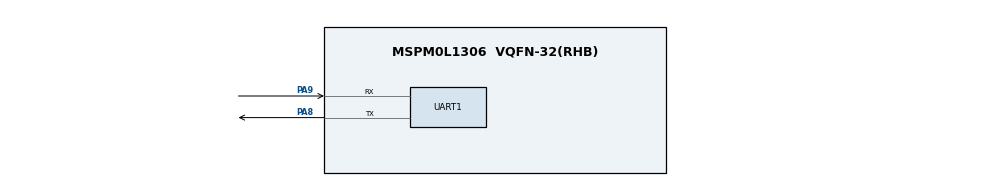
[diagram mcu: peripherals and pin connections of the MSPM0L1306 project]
// @cliArgs --board /ti/boards/LP_MSPM0L1306 --rtos nortos
//@cliArgs --device "MSPM0L130X" --package "VQFN-32(RHB)" --part "Default"
//@v2CliArgs --device "MSPM0L1306" --package "VQFN-32(RHB)"
// UART0 on PA8 (TX) / PA9 (RX), the XDS110 back-channel with J16/J17 on XDS.
// DMA ch0 = UART RX (byte -> memory), DMA ch1 = UART TX (memory -> byte).
// Baud rate is NOT set here: usart_dma.c overrides it from the build-time define USART_BAUD.
const SYSCTL = scripting.addModule("/ti/driverlib/SYSCTL");
const UART   = scripting.addModule("/ti/driverlib/UART", {}, false);
const UART1  = UART.addInstance();
const TIMER  = scripting.addModule("/ti/driverlib/TIMER", {}, false);
const TIMER1 = TIMER.addInstance();

SYSCTL.clockTreeEn = true;

UART1.$name                             = "UART_0";
UART1.profile                           = "CONFIG_PROFILE_1";
UART1.peripheral.$assign                = "UART0";
UART1.peripheral.txPin.$assign          = "PA8";
UART1.peripheral.rxPin.$assign          = "PA9";
UART1.targetBaudRate                    = 115200;
UART1.enableInternalLoopback            = false;
UART1.enableFIFO                        = true;
UART1.rxFifoThreshold                   = "DL_UART_RX_FIFO_LEVEL_ONE_ENTRY";
UART1.txFifoThreshold                   = "DL_UART_TX_FIFO_LEVEL_ONE_ENTRY";
UART1.enabledInterrupts                 = ["DMA_DONE_RX","DMA_DONE_TX"];
UART1.enabledDMARXTriggers              = "DL_UART_DMA_INTERRUPT_RX";
UART1.enabledDMATXTriggers              = "DL_UART_DMA_INTERRUPT_TX";
UART1.enableDMARX                       = true;
UART1.enableDMATX                       = true;
UART1.DMA_CHANNEL_RX.$name              = "DMA_RX";
UART1.DMA_CHANNEL_RX.addressMode        = "f2b";
UART1.DMA_CHANNEL_RX.dstIncDec          = "INCREMENT";
UART1.DMA_CHANNEL_RX.dstLength          = "BYTE";
UART1.DMA_CHANNEL_RX.srcLength          = "BYTE";
UART1.DMA_CHANNEL_RX.peripheral.$assign = "DMA_CH0";
UART1.DMA_CHANNEL_TX.$name              = "DMA_TX";
UART1.DMA_CHANNEL_TX.addressMode        = "b2f";
UART1.DMA_CHANNEL_TX.srcIncDec          = "INCREMENT";
UART1.DMA_CHANNEL_TX.dstLength          = "BYTE";
UART1.DMA_CHANNEL_TX.srcLength          = "BYTE";
UART1.DMA_CHANNEL_TX.peripheral.$assign = "DMA_CH1";

// 1 ms tick: stands in for the IDLE-line interrupt (see usart_dma.c)
TIMER1.$name              = "TIMER_IDLE";
TIMER1.timerClkSrc        = "BUSCLK";
TIMER1.timerClkDiv        = 1;
TIMER1.timerClkPrescale   = 32;
TIMER1.timerMode          = "PERIODIC";
TIMER1.timerPeriod        = "1 ms";
TIMER1.interrupts         = ["ZERO"];
TIMER1.peripheral.$assign = "TIMG0";
